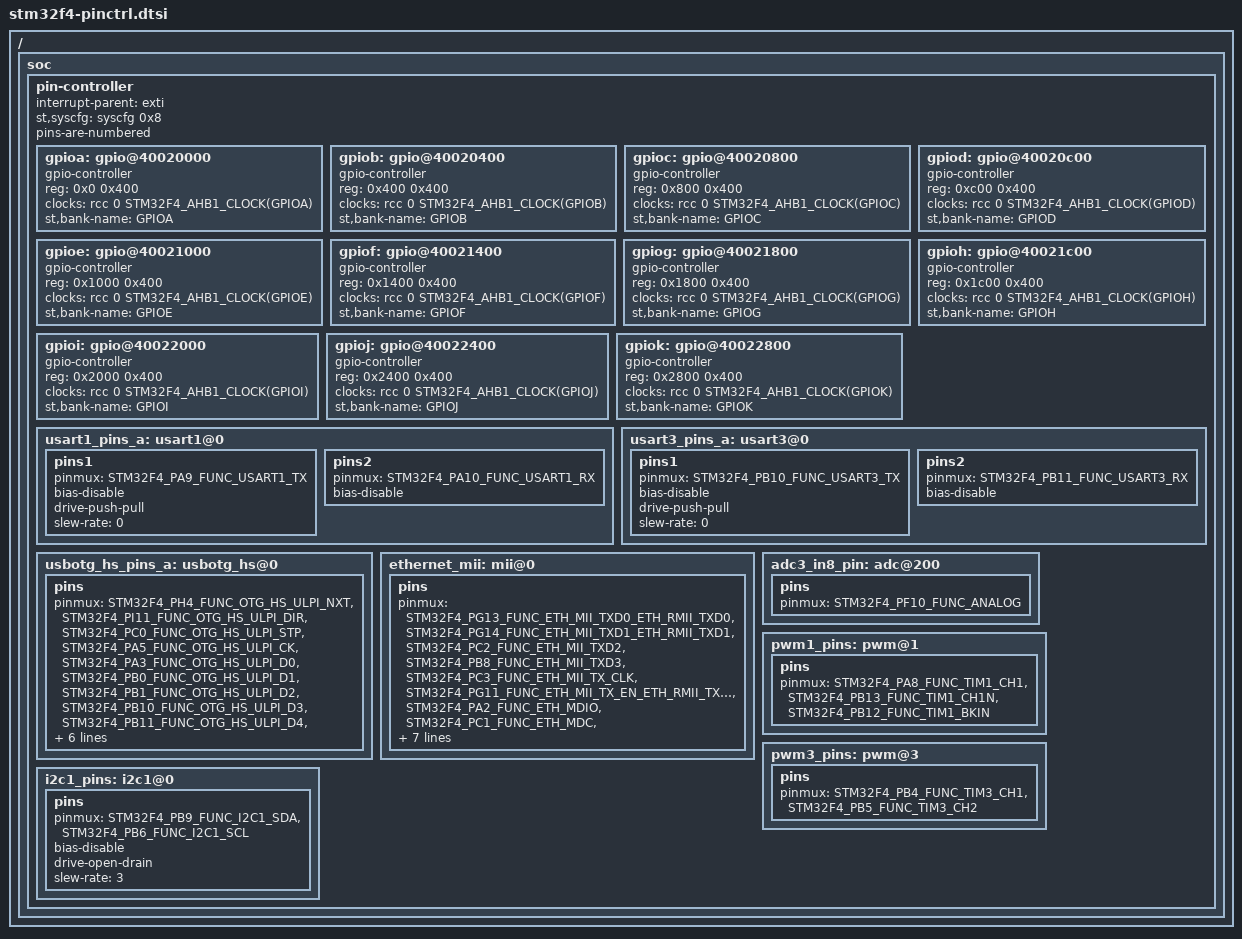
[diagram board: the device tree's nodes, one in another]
/*
 * Copyright 2016 - Alexandre Torgue <alexandre.torgue@st.com>
 *
 * This file is dual-licensed: you can use it either under the terms
 * of the GPL or the X11 license, at your option. Note that this dual
 * licensing only applies to this file, and not this project as a
 * whole.
 *
 *  a) This file is free software; you can redistribute it and/or
 *     modify it under the terms of the GNU General Public License as
 *     published by the Free Software Foundation; either version 2 of the
 *     License, or (at your option) any later version.
 *
 *     This file is distributed in the hope that it will be useful,
 *     but WITHOUT ANY WARRANTY; without even the implied warranty of
 *     MERCHANTABILITY or FITNESS FOR A PARTICULAR PURPOSE.  See the
 *     GNU General Public License for more details.
 *
 * Or, alternatively,
 *
 *  b) Permission is hereby granted, free of charge, to any person
 *     obtaining a copy of this software and associated documentation
 *     files (the "Software"), to deal in the Software without
 *     restriction, including without limitation the rights to use,
 *     copy, modify, merge, publish, distribute, sublicense, and/or
 *     sell copies of the Software, and to permit persons to whom the
 *     Software is furnished to do so, subject to the following
 *     conditions:
 *
 *     The above copyright notice and this permission notice shall be
 *     included in all copies or substantial portions of the Software.
 *
 *     THE SOFTWARE IS PROVIDED "AS IS", WITHOUT WARRANTY OF ANY KIND,
 *     EXPRESS OR IMPLIED, INCLUDING BUT NOT LIMITED TO THE WARRANTIES
 *     OF MERCHANTABILITY, FITNESS FOR A PARTICULAR PURPOSE AND
 *     NONINFRINGEMENT. IN NO EVENT SHALL THE AUTHORS OR COPYRIGHT
 *     HOLDERS BE LIABLE FOR ANY CLAIM, DAMAGES OR OTHER LIABILITY,
 *     WHETHER IN AN ACTION OF CONTRACT, TORT OR OTHERWISE, ARISING
 *     FROM, OUT OF OR IN CONNECTION WITH THE SOFTWARE OR THE USE OR
 *     OTHER DEALINGS IN THE SOFTWARE.
 */

#include <dt-bindings/pinctrl/stm32f4-pinfunc.h>
#include <dt-bindings/mfd/stm32f4-rcc.h>

/ {
	soc {

		pin-controller {
			#address-cells = <1>;
			#size-cells = <1>;
			ranges = <0 0x40020000 0x3000>;
			interrupt-parent = <&exti>;
			st,syscfg = <&syscfg 0x8>;
			pins-are-numbered;

			gpioa: gpio@40020000 {
				gpio-controller;
				#gpio-cells = <2>;
				reg = <0x0 0x400>;
				clocks = <&rcc 0 STM32F4_AHB1_CLOCK(GPIOA)>;
				st,bank-name = "GPIOA";
			};

			gpiob: gpio@40020400 {
				gpio-controller;
				#gpio-cells = <2>;
				reg = <0x400 0x400>;
				clocks = <&rcc 0 STM32F4_AHB1_CLOCK(GPIOB)>;
				st,bank-name = "GPIOB";
			};

			gpioc: gpio@40020800 {
				gpio-controller;
				#gpio-cells = <2>;
				reg = <0x800 0x400>;
				clocks = <&rcc 0 STM32F4_AHB1_CLOCK(GPIOC)>;
				st,bank-name = "GPIOC";
			};

			gpiod: gpio@40020c00 {
				gpio-controller;
				#gpio-cells = <2>;
				reg = <0xc00 0x400>;
				clocks = <&rcc 0 STM32F4_AHB1_CLOCK(GPIOD)>;
				st,bank-name = "GPIOD";
			};

			gpioe: gpio@40021000 {
				gpio-controller;
				#gpio-cells = <2>;
				reg = <0x1000 0x400>;
				clocks = <&rcc 0 STM32F4_AHB1_CLOCK(GPIOE)>;
				st,bank-name = "GPIOE";
			};

			gpiof: gpio@40021400 {
				gpio-controller;
				#gpio-cells = <2>;
				reg = <0x1400 0x400>;
				clocks = <&rcc 0 STM32F4_AHB1_CLOCK(GPIOF)>;
				st,bank-name = "GPIOF";
			};

			gpiog: gpio@40021800 {
				gpio-controller;
				#gpio-cells = <2>;
				reg = <0x1800 0x400>;
				clocks = <&rcc 0 STM32F4_AHB1_CLOCK(GPIOG)>;
				st,bank-name = "GPIOG";
			};

			gpioh: gpio@40021c00 {
				gpio-controller;
				#gpio-cells = <2>;
				reg = <0x1c00 0x400>;
				clocks = <&rcc 0 STM32F4_AHB1_CLOCK(GPIOH)>;
				st,bank-name = "GPIOH";
			};

			gpioi: gpio@40022000 {
				gpio-controller;
				#gpio-cells = <2>;
				reg = <0x2000 0x400>;
				clocks = <&rcc 0 STM32F4_AHB1_CLOCK(GPIOI)>;
				st,bank-name = "GPIOI";
			};

			gpioj: gpio@40022400 {
				gpio-controller;
				#gpio-cells = <2>;
				reg = <0x2400 0x400>;
				clocks = <&rcc 0 STM32F4_AHB1_CLOCK(GPIOJ)>;
				st,bank-name = "GPIOJ";
			};

			gpiok: gpio@40022800 {
				gpio-controller;
				#gpio-cells = <2>;
				reg = <0x2800 0x400>;
				clocks = <&rcc 0 STM32F4_AHB1_CLOCK(GPIOK)>;
				st,bank-name = "GPIOK";
			};

			usart1_pins_a: usart1@0 {
				pins1 {
					pinmux = <STM32F4_PA9_FUNC_USART1_TX>;
					bias-disable;
					drive-push-pull;
					slew-rate = <0>;
				};
				pins2 {
					pinmux = <STM32F4_PA10_FUNC_USART1_RX>;
					bias-disable;
				};
			};

			usart3_pins_a: usart3@0 {
				pins1 {
					pinmux = <STM32F4_PB10_FUNC_USART3_TX>;
					bias-disable;
					drive-push-pull;
					slew-rate = <0>;
				};
				pins2 {
					pinmux = <STM32F4_PB11_FUNC_USART3_RX>;
					bias-disable;
				};
			};

			usbotg_hs_pins_a: usbotg_hs@0 {
				pins {
					pinmux = <STM32F4_PH4_FUNC_OTG_HS_ULPI_NXT>,
						 <STM32F4_PI11_FUNC_OTG_HS_ULPI_DIR>,
						 <STM32F4_PC0_FUNC_OTG_HS_ULPI_STP>,
						 <STM32F4_PA5_FUNC_OTG_HS_ULPI_CK>,
						 <STM32F4_PA3_FUNC_OTG_HS_ULPI_D0>,
						 <STM32F4_PB0_FUNC_OTG_HS_ULPI_D1>,
						 <STM32F4_PB1_FUNC_OTG_HS_ULPI_D2>,
						 <STM32F4_PB10_FUNC_OTG_HS_ULPI_D3>,
						 <STM32F4_PB11_FUNC_OTG_HS_ULPI_D4>,
						 <STM32F4_PB12_FUNC_OTG_HS_ULPI_D5>,
						 <STM32F4_PB13_FUNC_OTG_HS_ULPI_D6>,
						 <STM32F4_PB5_FUNC_OTG_HS_ULPI_D7>;
					bias-disable;
					drive-push-pull;
					slew-rate = <2>;
				};
			};

			ethernet_mii: mii@0 {
				pins {
					pinmux = <STM32F4_PG13_FUNC_ETH_MII_TXD0_ETH_RMII_TXD0>,
						 <STM32F4_PG14_FUNC_ETH_MII_TXD1_ETH_RMII_TXD1>,
						 <STM32F4_PC2_FUNC_ETH_MII_TXD2>,
						 <STM32F4_PB8_FUNC_ETH_MII_TXD3>,
						 <STM32F4_PC3_FUNC_ETH_MII_TX_CLK>,
						 <STM32F4_PG11_FUNC_ETH_MII_TX_EN_ETH_RMII_TX_EN>,
						 <STM32F4_PA2_FUNC_ETH_MDIO>,
						 <STM32F4_PC1_FUNC_ETH_MDC>,
						 <STM32F4_PA1_FUNC_ETH_MII_RX_CLK_ETH_RMII_REF_CLK>,
						 <STM32F4_PA7_FUNC_ETH_MII_RX_DV_ETH_RMII_CRS_DV>,
						 <STM32F4_PC4_FUNC_ETH_MII_RXD0_ETH_RMII_RXD0>,
						 <STM32F4_PC5_FUNC_ETH_MII_RXD1_ETH_RMII_RXD1>,
						 <STM32F4_PH6_FUNC_ETH_MII_RXD2>,
						 <STM32F4_PH7_FUNC_ETH_MII_RXD3>;
					slew-rate = <2>;
				};
			};

			adc3_in8_pin: adc@200 {
				pins {
					pinmux = <STM32F4_PF10_FUNC_ANALOG>;
				};
			};

			pwm1_pins: pwm@1 {
				pins {
					pinmux = <STM32F4_PA8_FUNC_TIM1_CH1>,
						 <STM32F4_PB13_FUNC_TIM1_CH1N>,
						 <STM32F4_PB12_FUNC_TIM1_BKIN>;
				};
			};

			pwm3_pins: pwm@3 {
				pins {
					pinmux = <STM32F4_PB4_FUNC_TIM3_CH1>,
						 <STM32F4_PB5_FUNC_TIM3_CH2>;
				};
			};

			i2c1_pins: i2c1@0 {
				pins {
					pinmux = <STM32F4_PB9_FUNC_I2C1_SDA>,
						 <STM32F4_PB6_FUNC_I2C1_SCL>;
					bias-disable;
					drive-open-drain;
					slew-rate = <3>;
				};
			};
		};
	};
};
